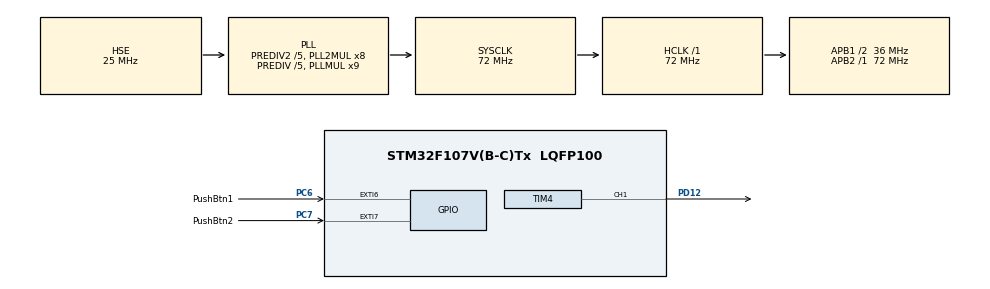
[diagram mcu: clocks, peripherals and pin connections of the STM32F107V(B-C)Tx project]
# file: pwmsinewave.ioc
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Mcu.Family=STM32F1
Mcu.Name=STM32F107V(B-C)Tx
Mcu.Package=LQFP100
NVIC.EXTI9_5_IRQn=true\:0\:0\:false\:false\:true\:true
NVIC.PriorityGroup=NVIC_PRIORITYGROUP_4
NVIC.TIM4_IRQn=true\:0\:0\:false\:false\:true\:true
OSC_IN.Mode=HSE-External-Oscillator
OSC_IN.Signal=RCC_OSC_IN
OSC_OUT.Mode=HSE-External-Oscillator
OSC_OUT.Signal=RCC_OSC_OUT
PA13.Mode=Serial_Wire
PA13.Signal=SYS_JTMS-SWDIO
PA14.Mode=Serial_Wire
PA14.Signal=SYS_JTCK-SWCLK
PC6.GPIO_Label=PushBtn1
PC6.GPIO_ModeDefaultEXTI=GPIO_MODE_IT_FALLING
PC6.Signal=GPXTI6
PC7.GPIO_Label=PushBtn2
PC7.Signal=GPXTI7
PD12.Signal=S_TIM4_CH1
PD13.Signal=S_TIM4_CH2
PD14.Signal=S_TIM4_CH3
ProjectManager.HeapSize=0x200
ProjectManager.StackSize=0x400
ProjectManager.TargetToolchain=MDK-ARM V5
RCC.AHBFreq_Value=72000000
RCC.APB1CLKDivider=RCC_HCLK_DIV2
RCC.APB1Freq_Value=36000000
RCC.APB1TimFreq_Value=72000000
RCC.APB2Freq_Value=72000000
RCC.APB2TimFreq_Value=72000000
RCC.HCLKFreq_Value=72000000
RCC.HSEDivPLL=RCC_HSE_PREDIV_DIV5
RCC.HSE_VALUE=25000000
RCC.PLLMUL=RCC_PLL_MUL9
RCC.PLLSourceVirtual=RCC_PLLSOURCE_HSE
RCC.Prediv1Source=RCC_PREDIV1_SOURCE_PLL2
RCC.Prediv2=RCC_HSE_PREDIV2_DIV5
RCC.SYSCLKFreq_VALUE=72000000
RCC.SYSCLKSource=RCC_SYSCLKSOURCE_PLLCLK
RCC.USBFreq_Value=48000000
SH.S_TIM4_CH1.0=TIM4_CH1,PWM Generation1 CH1
SH.S_TIM4_CH2.0=TIM4_CH2
SH.S_TIM4_CH3.0=TIM4_CH3
TIM4.AutoReloadPreload=TIM_AUTORELOAD_PRELOAD_ENABLE
TIM4.Channel-PWM\ Generation1\ CH1=TIM_CHANNEL_1
TIM4.OCPolarity_1=TIM_OCPOLARITY_LOW
TIM4.Period=5000
TIM4.Prescaler=71
TIM4.Pulse-PWM\ Generation1\ CH1=49
VP_TIM4_VS_ClockSourceINT.Mode=Internal
board=pwmsinewave

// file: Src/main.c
/**
  ******************************************************************************
  * @file           : main.c
  * @brief          : Main program body
  ******************************************************************************
  ** This notice applies to any and all portions of this file
  * that are not between comment pairs USER CODE BEGIN and
  * USER CODE END. Other portions of this file, whether
  * inserted by the user or by software development tools
  * are owned by their respective copyright owners.
  *
  * COPYRIGHT(c) 2018 STMicroelectronics
  *
  * Redistribution and use in source and binary forms, with or without modification,
  * are permitted provided that the following conditions are met:
  *   1. Redistributions of source code must retain the above copyright notice,
  *      this list of conditions and the following disclaimer.
  *   2. Redistributions in binary form must reproduce the above copyright notice,
  *      this list of conditions and the following disclaimer in the documentation
  *      and/or other materials provided with the distribution.
  *   3. Neither the name of STMicroelectronics nor the names of its contributors
  *      may be used to endorse or promote products derived from this software
  *      without specific prior written permission.
  *
  * THIS SOFTWARE IS PROVIDED BY THE COPYRIGHT HOLDERS AND CONTRIBUTORS "AS IS"
  * AND ANY EXPRESS OR IMPLIED WARRANTIES, INCLUDING, BUT NOT LIMITED TO, THE
  * IMPLIED WARRANTIES OF MERCHANTABILITY AND FITNESS FOR A PARTICULAR PURPOSE ARE
  * DISCLAIMED. IN NO EVENT SHALL THE COPYRIGHT HOLDER OR CONTRIBUTORS BE LIABLE
  * FOR ANY DIRECT, INDIRECT, INCIDENTAL, SPECIAL, EXEMPLARY, OR CONSEQUENTIAL
  * DAMAGES (INCLUDING, BUT NOT LIMITED TO, PROCUREMENT OF SUBSTITUTE GOODS OR
  * SERVICES; LOSS OF USE, DATA, OR PROFITS; OR BUSINESS INTERRUPTION) HOWEVER
  * CAUSED AND ON ANY THEORY OF LIABILITY, WHETHER IN CONTRACT, STRICT LIABILITY,
  * OR TORT (INCLUDING NEGLIGENCE OR OTHERWISE) ARISING IN ANY WAY OUT OF THE USE
  * OF THIS SOFTWARE, EVEN IF ADVISED OF THE POSSIBILITY OF SUCH DAMAGE.
  *
  ******************************************************************************
  */
#include "main.h"
#include "stm32f1xx_hal.h"

TIM_HandleTypeDef htim4;

/* USER CODE BEGIN PV */
/* Private variables ---------------------------------------------------------*/
int pwmsine[210]={
2500,2575,2650,2725,2800,2874,2949,3022,
3095,3168,3240,3312,3382,3452,3521,3590,
3657,3723,3788,3852,3914,3976,4036,4094,
4151,4207,4261,4314,4365,4414,4461,4507,
4551,4593,4633,4671,4708,4742,4774,4804,
4832,4858,4882,4904,4924,4941,4956,4969,
4980,4988,4994,4998,5000,4999,4997,4991,
4984,4975,4963,4949,4932,4914,4893,4871,
4846,4819,4789,4758,4725,4690,4652,4613,
4572,4529,4484,4438,4389,4339,4288,4234,
4179,4123,4065,4006,3945,3883,3820,3755,
3690,3623,3556,3487,3418,3347,3276,3204,
3132,3059,2985,2911,2837,2763,2688,2613,
2538,2462,2387,2312,2237,2163,2089,2015,
1941,1868,1796,1724,1653,1582,1513,1444,
1377,1310,1245,1180,1117,1055,994,935,
877,821,766,712,661,611,562,516,
471,428,387,348,310,275,242,211,
181,154,129,107,86,68,51,37,
25,16,9,3,1,0,2,6,
12,20,31,44,59,76,96,118,
142,168,196,226,258,292,329,367,
407,449,493,539,586,635,686,739,
793,849,906,964,1024,1086,1148,1212,
1277,1343,1410,1479,1548,1618,1688,1760,
1832,1905,1978,2051,2126,2200,2275,2350,
2425,2500};

static int i = 0;

/* USER CODE END PV */

void SystemClock_Config(void);
static void MX_GPIO_Init(void);
static void MX_TIM4_Init(void);
void HAL_TIM_MspPostInit(TIM_HandleTypeDef *htim);

/* USER CODE BEGIN PFP */
/* Private function prototypes -----------------------------------------------*/
/**
  * @brief  Input Capture callback in non blocking mode
  * @param  htim : TIM IC handle
  * @retval None
  */
void HAL_TIM_PWM_PulseFinishedCallback(TIM_HandleTypeDef *htim)
{

	htim->Instance->CCR1 = pwmsine[i];

	i++;

	if( i == 210 )
		i = 0;
  /* Prevent unused argument(s) compilation warning */
  //UNUSED(htim);
  /* NOTE : This function Should not be modified, when the callback is needed,
            the __HAL_TIM_IC_CaptureCallback could be implemented in the user file
   */
}

/* USER CODE END PFP */

int main(void)
{

  /* MCU Configuration----------------------------------------------------------*/

  /* Reset of all peripherals, Initializes the Flash interface and the Systick. */
  HAL_Init();

  /* Configure the system clock */
  SystemClock_Config();

  /* Initialize all configured peripherals */
  MX_GPIO_Init();
  MX_TIM4_Init();
  /* USER CODE BEGIN 2 */

	HAL_TIM_IC_Start_IT(&htim4,TIM_CHANNEL_1);

	HAL_TIM_PWM_Start(&htim4,TIM_CHANNEL_1);

  /* USER CODE END 2 */

  /* Infinite loop */
  while (1)
  {

  }

}

void SystemClock_Config(void)
{

  RCC_OscInitTypeDef RCC_OscInitStruct;
  RCC_ClkInitTypeDef RCC_ClkInitStruct;

    /**Initializes the CPU, AHB and APB busses clocks
    */
  RCC_OscInitStruct.OscillatorType = RCC_OSCILLATORTYPE_HSE;
  RCC_OscInitStruct.HSEState = RCC_HSE_ON;
  RCC_OscInitStruct.HSEPredivValue = RCC_HSE_PREDIV_DIV5;
  RCC_OscInitStruct.HSIState = RCC_HSI_ON;
  RCC_OscInitStruct.Prediv1Source = RCC_PREDIV1_SOURCE_PLL2;
  RCC_OscInitStruct.PLL.PLLState = RCC_PLL_ON;
  RCC_OscInitStruct.PLL.PLLSource = RCC_PLLSOURCE_HSE;
  RCC_OscInitStruct.PLL.PLLMUL = RCC_PLL_MUL9;
  RCC_OscInitStruct.PLL2.PLL2State = RCC_PLL2_ON;
  RCC_OscInitStruct.PLL2.PLL2MUL = RCC_PLL2_MUL8;
  RCC_OscInitStruct.PLL2.HSEPrediv2Value = RCC_HSE_PREDIV2_DIV5;
  if (HAL_RCC_OscConfig(&RCC_OscInitStruct) != HAL_OK)
  {
    _Error_Handler(__FILE__, __LINE__);
  }

    /**Initializes the CPU, AHB and APB busses clocks
    */
  RCC_ClkInitStruct.ClockType = RCC_CLOCKTYPE_HCLK|RCC_CLOCKTYPE_SYSCLK
                              |RCC_CLOCKTYPE_PCLK1|RCC_CLOCKTYPE_PCLK2;
  RCC_ClkInitStruct.SYSCLKSource = RCC_SYSCLKSOURCE_PLLCLK;
  RCC_ClkInitStruct.AHBCLKDivider = RCC_SYSCLK_DIV1;
  RCC_ClkInitStruct.APB1CLKDivider = RCC_HCLK_DIV2;
  RCC_ClkInitStruct.APB2CLKDivider = RCC_HCLK_DIV1;

  if (HAL_RCC_ClockConfig(&RCC_ClkInitStruct, FLASH_LATENCY_2) != HAL_OK)
  {
    _Error_Handler(__FILE__, __LINE__);
  }

    /**Configure the Systick interrupt time
    */
  HAL_SYSTICK_Config(HAL_RCC_GetHCLKFreq()/1000);

    /**Configure the Systick
    */
  HAL_SYSTICK_CLKSourceConfig(SYSTICK_CLKSOURCE_HCLK);

    /**Configure the Systick interrupt time
    */
  __HAL_RCC_PLLI2S_ENABLE();

  /* SysTick_IRQn interrupt configuration */
  HAL_NVIC_SetPriority(SysTick_IRQn, 0, 0);
}

/* TIM4 init function */
static void MX_TIM4_Init(void)
{

  TIM_ClockConfigTypeDef sClockSourceConfig;
  TIM_MasterConfigTypeDef sMasterConfig;
  TIM_OC_InitTypeDef sConfigOC;

  htim4.Instance = TIM4;
  htim4.Init.Prescaler = 71;
  htim4.Init.CounterMode = TIM_COUNTERMODE_UP;
  htim4.Init.Period = 5000;
  htim4.Init.ClockDivision = TIM_CLOCKDIVISION_DIV1;
  htim4.Init.AutoReloadPreload = TIM_AUTORELOAD_PRELOAD_ENABLE;
  if (HAL_TIM_Base_Init(&htim4) != HAL_OK)
  {
    _Error_Handler(__FILE__, __LINE__);
  }

  sClockSourceConfig.ClockSource = TIM_CLOCKSOURCE_INTERNAL;
  if (HAL_TIM_ConfigClockSource(&htim4, &sClockSourceConfig) != HAL_OK)
  {
    _Error_Handler(__FILE__, __LINE__);
  }

  if (HAL_TIM_PWM_Init(&htim4) != HAL_OK)
  {
    _Error_Handler(__FILE__, __LINE__);
  }

  sMasterConfig.MasterOutputTrigger = TIM_TRGO_RESET;
  sMasterConfig.MasterSlaveMode = TIM_MASTERSLAVEMODE_DISABLE;
  if (HAL_TIMEx_MasterConfigSynchronization(&htim4, &sMasterConfig) != HAL_OK)
  {
    _Error_Handler(__FILE__, __LINE__);
  }

  sConfigOC.OCMode = TIM_OCMODE_PWM1;
  sConfigOC.Pulse = 49;
  sConfigOC.OCPolarity = TIM_OCPOLARITY_LOW;
  sConfigOC.OCFastMode = TIM_OCFAST_DISABLE;
  if (HAL_TIM_PWM_ConfigChannel(&htim4, &sConfigOC, TIM_CHANNEL_1) != HAL_OK)
  {
    _Error_Handler(__FILE__, __LINE__);
  }

  HAL_TIM_MspPostInit(&htim4);

}

/** Configure pins as
        * Analog
        * Input
        * Output
        * EVENT_OUT
        * EXTI
*/
static void MX_GPIO_Init(void)
{

  GPIO_InitTypeDef GPIO_InitStruct;

  /* GPIO Ports Clock Enable */
  __HAL_RCC_GPIOD_CLK_ENABLE();
  __HAL_RCC_GPIOC_CLK_ENABLE();
  __HAL_RCC_GPIOA_CLK_ENABLE();

  /*Configure GPIO pin : PushBtn1_Pin */
  GPIO_InitStruct.Pin = PushBtn1_Pin;
  GPIO_InitStruct.Mode = GPIO_MODE_IT_FALLING;
  GPIO_InitStruct.Pull = GPIO_NOPULL;
  HAL_GPIO_Init(PushBtn1_GPIO_Port, &GPIO_InitStruct);

  /*Configure GPIO pin : PushBtn2_Pin */
  GPIO_InitStruct.Pin = PushBtn2_Pin;
  GPIO_InitStruct.Mode = GPIO_MODE_IT_RISING;
  GPIO_InitStruct.Pull = GPIO_NOPULL;
  HAL_GPIO_Init(PushBtn2_GPIO_Port, &GPIO_InitStruct);

  /* EXTI interrupt init*/
  HAL_NVIC_SetPriority(EXTI9_5_IRQn, 0, 0);
  HAL_NVIC_EnableIRQ(EXTI9_5_IRQn);

}

void _Error_Handler(char *file, int line)
{
  while(1)
  {
  }
}

/************************ (C) COPYRIGHT STMicroelectronics *****END OF FILE****/
